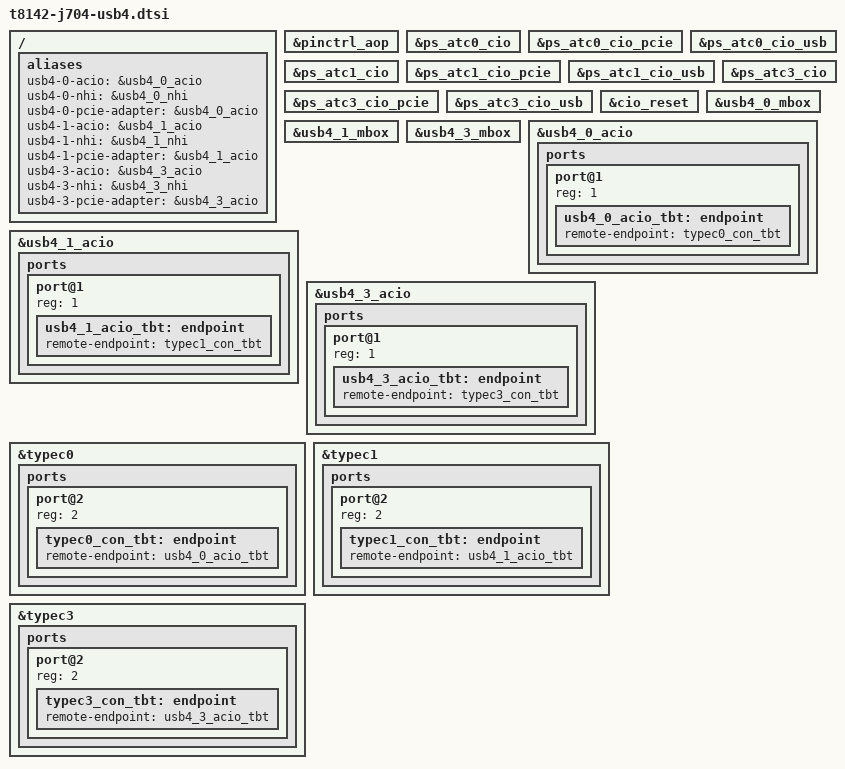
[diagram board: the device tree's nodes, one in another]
// SPDX-License-Identifier: GPL-2.0+ OR MIT
/*
 * J704 USB4/Thunderbolt: ACIO0, ACIO1 and ACIO3 behind the three Type-C
 * ports (hpm0/ATC0, hpm1/ATC1, hpm3/ATC3). ACIO powers its domains only
 * once the port controller reports a USB4 or Thunderbolt connection.
 *
 * Copyright The Asahi Linux Contributors
 */

/ {
	aliases {
		usb4-0-acio = &usb4_0_acio;
		usb4-0-nhi = &usb4_0_nhi;
		usb4-0-pcie-adapter = &usb4_0_acio;
		usb4-1-acio = &usb4_1_acio;
		usb4-1-nhi = &usb4_1_nhi;
		usb4-1-pcie-adapter = &usb4_1_acio;
		usb4-3-acio = &usb4_3_acio;
		usb4-3-nhi = &usb4_3_nhi;
		usb4-3-pcie-adapter = &usb4_3_acio;
	};
};

&pinctrl_aop {
	status = "okay";
};

/* ACIO is the consumer that owns these domains while a cable is up. */
&ps_atc0_cio {
	status = "okay";
};

&ps_atc0_cio_pcie {
	status = "okay";
};

&ps_atc0_cio_usb {
	status = "okay";
};

&ps_atc1_cio {
	status = "okay";
};

&ps_atc1_cio_pcie {
	status = "okay";
};

&ps_atc1_cio_usb {
	status = "okay";
};

&ps_atc3_cio {
	status = "okay";
};

&ps_atc3_cio_pcie {
	status = "okay";
};

&ps_atc3_cio_usb {
	status = "okay";
};

&cio_reset {
	status = "okay";
};

&usb4_0_mbox {
	status = "okay";
};

&usb4_1_mbox {
	status = "okay";
};

&usb4_3_mbox {
	status = "okay";
};

&usb4_0_acio {
	status = "okay";

	ports {
		#address-cells = <1>;
		#size-cells = <0>;

		/* 1: USB4 port */
		port@1 {
			reg = <1>;
			usb4_0_acio_tbt: endpoint {
				remote-endpoint = <&typec0_con_tbt>;
			};
		};
	};
};

&usb4_1_acio {
	status = "okay";

	ports {
		#address-cells = <1>;
		#size-cells = <0>;

		port@1 {
			reg = <1>;
			usb4_1_acio_tbt: endpoint {
				remote-endpoint = <&typec1_con_tbt>;
			};
		};
	};
};

&usb4_3_acio {
	status = "okay";

	ports {
		#address-cells = <1>;
		#size-cells = <0>;

		port@1 {
			reg = <1>;
			usb4_3_acio_tbt: endpoint {
				remote-endpoint = <&typec3_con_tbt>;
			};
		};
	};
};

&typec0 {
	ports {
		port@2 {
			reg = <2>;
			typec0_con_tbt: endpoint {
				remote-endpoint = <&usb4_0_acio_tbt>;
			};
		};
	};
};

&typec1 {
	ports {
		port@2 {
			reg = <2>;
			typec1_con_tbt: endpoint {
				remote-endpoint = <&usb4_1_acio_tbt>;
			};
		};
	};
};

&typec3 {
	ports {
		port@2 {
			reg = <2>;
			typec3_con_tbt: endpoint {
				remote-endpoint = <&usb4_3_acio_tbt>;
			};
		};
	};
};
